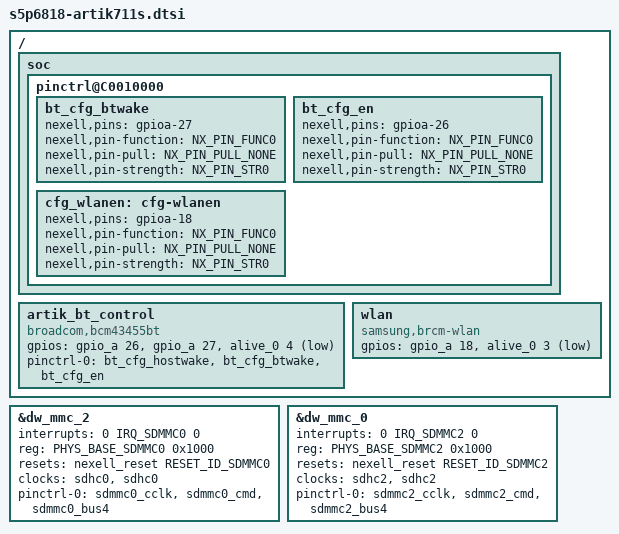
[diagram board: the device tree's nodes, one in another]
/*
 * Copyright (C) 2018 Samsung Electronics
 * Author: Chanho Park <chanho61.park@samsung.com>
 *
 * This program is free software; you can redistribute it and/or
 * modify it under the terms of the GNU General Public License
 * as published by the Free Software Foundation; either version 2
 * of the License, or (at your option) any later version.
 *
 * This program is distributed in the hope that it will be useful,
 * but WITHOUT ANY WARRANTY; without even the implied warranty of
 * MERCHANTABILITY or FITNESS FOR A PARTICULAR PURPOSE.  See the
 * GNU General Public License for more details.
 *
 * You should have received a copy of the GNU General Public License
 * along with this program.  If not, see <http://www.gnu.org/licenses/>.
 */
#include "s5p6818-artik710.dtsi"

/ {
	soc {
		pinctrl@C0010000 {
			bt_cfg_btwake:bt_cfg_btwake {
				nexell,pins = "gpioa-27";
				nexell,pin-function = <NX_PIN_FUNC0>;
				nexell,pin-pull = <NX_PIN_PULL_NONE>;
				nexell,pin-strength = <NX_PIN_STR0>;
			};

			bt_cfg_en:bt_cfg_en {
				nexell,pins = "gpioa-26";
				nexell,pin-function = <NX_PIN_FUNC0>;
				nexell,pin-pull = <NX_PIN_PULL_NONE>;
				nexell,pin-strength = <NX_PIN_STR0>;
			};

			cfg_wlanen: cfg-wlanen {
				nexell,pins = "gpioa-18";
				nexell,pin-function = <NX_PIN_FUNC0>;
				nexell,pin-pull = <NX_PIN_PULL_NONE>;
				nexell,pin-strength = <NX_PIN_STR0>;
			};
		};
	}; /* soc */

	artik_bt_control {
		compatible = "broadcom,bcm43455bt";
		gpios = <&gpio_a 26 0	/* GPIOA26=BT_EN, output */
			&gpio_a 27 0	/* GPIOA27=BT_WAKE, output */
			&alive_0 4 1	/* AliveGPIO4=BT_HOST_WAKE, input */
			>;
		pinctrl-names = "default";
		pinctrl-0 = <&bt_cfg_hostwake &bt_cfg_btwake &bt_cfg_en>;
		status = "okay";
	};

	wlan {
		compatible = "samsung,brcm-wlan";
		gpios = <&gpio_a 18 0	/* WLAN_EN */
			&alive_0 3 1>;	/* WLAN_HOST_WAKE */
		status = "okay";
	};
};

&dw_mmc_2 {
	interrupts = <0 IRQ_SDMMC0 0>;
	reg = <PHYS_BASE_SDMMC0 0x1000>;
	resets  = <&nexell_reset RESET_ID_SDMMC0>;
	clocks = <&sdhc0>, <&sdhc0>;
	pinctrl-0 = <&sdmmc0_cclk &sdmmc0_cmd &sdmmc0_bus4>;
};

&dw_mmc_0 {
	interrupts = <0 IRQ_SDMMC2 0>;
	reg = <PHYS_BASE_SDMMC2 0x1000>;
	resets  = <&nexell_reset RESET_ID_SDMMC2>;
	clocks = <&sdhc2>, <&sdhc2>;
	pinctrl-0 = <&sdmmc2_cclk &sdmmc2_cmd &sdmmc2_bus4>;
};
